AUTOSAR XML (schema 00044)
package /ComponentTypes
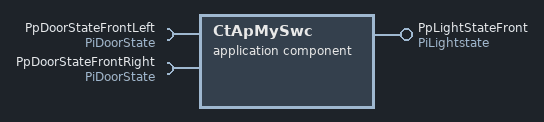
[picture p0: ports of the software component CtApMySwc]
  application sw component type CtApMySwc
    provide port PpLightStateFront: nonqueued-sender-com-spec{data-element=DeLightstate, init-value=constant-reference=Clightoff}, provided-interface=PiLightstate
    require port PpDoorStateFrontLeft: nonqueued-receiver-com-spec{data-element=DeDoorState, init-value=constant-reference=CDoorClosed}, required-interface=PiDoorState
    require port PpDoorStateFrontRight: nonqueued-receiver-com-spec{data-element=DeDoorState, init-value=constant-reference=CDoorClosed}, required-interface=PiDoorState
    behavior CtApMySwc_InternalBehavior: data-type-mapping=DemoTypeMapping
  swc implementation CtApMySwc_Implementation: behavior=CtApMySwc_InternalBehavior
